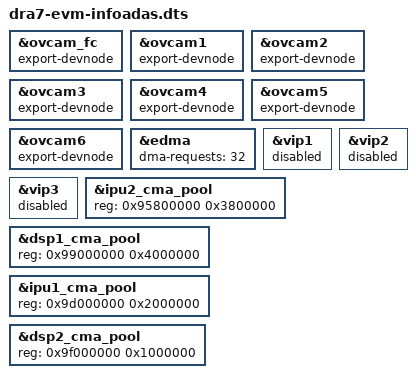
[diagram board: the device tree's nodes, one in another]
/*
 * Copyright (C) 2013 Texas Instruments Incorporated - http://www.ti.com/
 *
 * This program is free software; you can redistribute it and/or modify
 * it under the terms of the GNU General Public License version 2 as
 * published by the Free Software Foundation.
 */
#include "dra7-evm-vision.dts"

&ovcam_fc {
	export-devnode;
};

&ovcam1 {
	export-devnode;
};

&ovcam2 {
	export-devnode;
};

&ovcam3 {
	export-devnode;
};

&ovcam4 {
	export-devnode;
};

&ovcam5 {
	export-devnode;
};

&ovcam6 {
	export-devnode;
};

/delete-node/ &vpe;

/*
 * Restrict the linux used EDMA requests to only 32
 * Last 32 requests lines would be routed by the edma-xbar
 * to perform DMA for DSPs and IPUs
 */
&edma {
	dma-requests = <32>;
};

&vip1 {
	status = "disabled";
};

&vip2 {
	status = "disabled";
};

&vip3 {
	status = "disabled";
};

&ipu2_cma_pool {
	reg = <0x95800000 0x3800000>;
};

&dsp1_cma_pool {
	reg = <0x99000000 0x4000000>;
};

&ipu1_cma_pool {
	reg = <0x9d000000 0x2000000>;
};

&dsp2_cma_pool {
	reg = <0x9f000000 0x1000000>;
};
